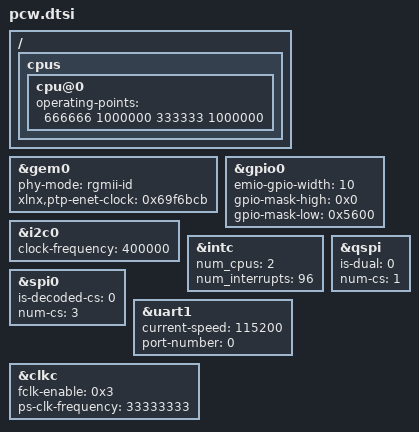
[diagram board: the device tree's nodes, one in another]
/*
 * CAUTION: This file is automatically generated by Xilinx.
 * Version: HSI 2015.4
 * Today is: Wed Mar 14 15:48:56 2018
*/


/ {
	cpus {
		cpu@0 {
			operating-points = <666666 1000000 333333 1000000>;
		};
	};
};
&gem0 {
	phy-mode = "rgmii-id";
	status = "okay";
	xlnx,ptp-enet-clock = <0x69f6bcb>;
};
&gpio0 {
	emio-gpio-width = <10>;
	gpio-mask-high = <0x0>;
	gpio-mask-low = <0x5600>;
};
&i2c0 {
	clock-frequency = <400000>;
	status = "okay";
};
&intc {
	num_cpus = <2>;
	num_interrupts = <96>;
};
&qspi {
	is-dual = <0>;
	num-cs = <1>;
	status = "okay";
};
&spi0 {
	is-decoded-cs = <0>;
	num-cs = <3>;
	status = "okay";
};
&uart1 {
	current-speed = <115200>;
	device_type = "serial";
	port-number = <0>;
	status = "okay";
};
&clkc {
	fclk-enable = <0x3>;
	ps-clk-frequency = <33333333>;
};
